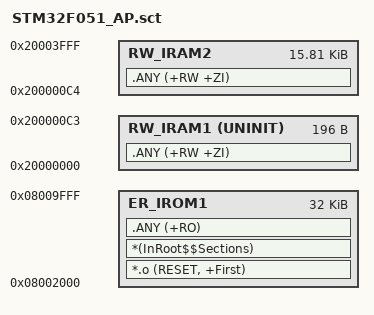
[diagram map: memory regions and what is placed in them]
; *************************************************************
; *** Scatter-Loading Description File generated by uVision ***
; *************************************************************

LR_IROM1 0x08002000 0x00008000  {    ; load region size_region
  ER_IROM1 0x08002000 0x00008000  {  ; load address = execution address
   *.o (RESET, +First)
   *(InRoot$$Sections)
   .ANY (+RO)
  }
  RW_IRAM1 0x20000000 UNINIT 0x000000C4  {  ; RW data
   .ANY (+RW +ZI)
  }
  RW_IRAM2 0x200000C4 0x00003F3C  {
   .ANY (+RW +ZI)
  }
}

